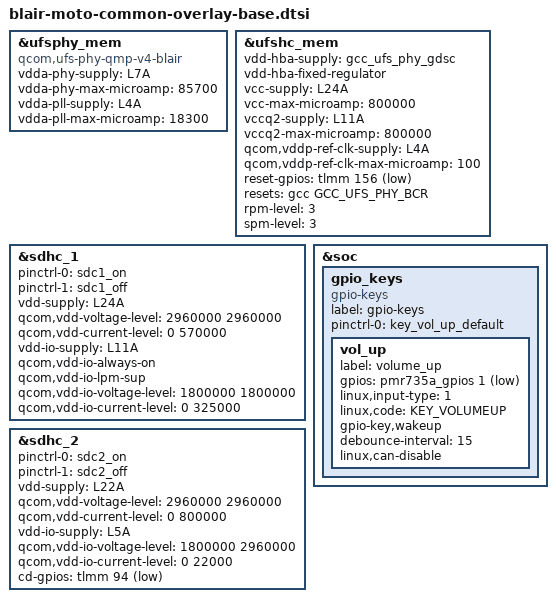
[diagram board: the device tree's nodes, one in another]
/*
   This base is original from "blair-mtp.dtsi"
*/

#include <dt-bindings/gpio/gpio.h>
#include <dt-bindings/input/linux-event-codes.h>
#include "blair-pmic-overlay-pm6125.dtsi"
#include <dt-bindings/clock/qcom,gcc-blair.h>

&ufsphy_mem {
	compatible = "qcom,ufs-phy-qmp-v4-blair";

	/* VDDA_UFS_CORE */
	vdda-phy-supply = <&L7A>;
	vdda-phy-max-microamp = <85700>;

	/* VDDA_UFS_0_1P2 */
	vdda-pll-supply = <&L4A>;
	vdda-pll-max-microamp = <18300>;

	status = "ok";
};

&ufshc_mem {
	vdd-hba-supply = <&gcc_ufs_phy_gdsc>;
	vdd-hba-fixed-regulator;

	vcc-supply = <&L24A>;
	vcc-max-microamp = <800000>;

	vccq2-supply = <&L11A>;
	vccq2-max-microamp = <800000>;

	/* VDD_PX10 is voted for the ufs_reset_n */
	qcom,vddp-ref-clk-supply = <&L4A>;
	qcom,vddp-ref-clk-max-microamp = <100>;

	reset-gpios = <&tlmm 156 GPIO_ACTIVE_LOW>;
	resets = <&gcc GCC_UFS_PHY_BCR>;
	reset-names = "rst";

        rpm-level = <3>;
        spm-level = <3>;

	status = "ok";
};

&sdhc_1 {
	status = "ok";

	pinctrl-names = "default", "sleep";
	pinctrl-0 = <&sdc1_on>;
	pinctrl-1 = <&sdc1_off>;

	vdd-supply = <&L24A>;
	qcom,vdd-voltage-level = <2960000 2960000>;
	qcom,vdd-current-level = <0 570000>;

	vdd-io-supply = <&L11A>;
	qcom,vdd-io-always-on;
	qcom,vdd-io-lpm-sup;
	qcom,vdd-io-voltage-level = <1800000 1800000>;
	qcom,vdd-io-current-level = <0 325000>;
};

&sdhc_2 {
	status = "ok";

	pinctrl-names = "default", "sleep";
	pinctrl-0 = <&sdc2_on>;
	pinctrl-1 = <&sdc2_off>;

	vdd-supply = <&L22A>;
	qcom,vdd-voltage-level = <2960000 2960000>;
	qcom,vdd-current-level = <0 800000>;

	vdd-io-supply = <&L5A>;
	qcom,vdd-io-voltage-level = <1800000 2960000>;
	qcom,vdd-io-current-level = <0 22000>;

	cd-gpios = <&tlmm 94 GPIO_ACTIVE_LOW>;
};


&soc {
	gpio_keys {
		compatible = "gpio-keys";
		label = "gpio-keys";

		pinctrl-names = "default";
		pinctrl-0 = <&key_vol_up_default>;

		vol_up {
			label = "volume_up";
			gpios = <&pmr735a_gpios 1 GPIO_ACTIVE_LOW>;
			linux,input-type = <1>;
			linux,code = <KEY_VOLUMEUP>;
			gpio-key,wakeup;
			debounce-interval = <15>;
			linux,can-disable;
		};
	};
};
